# ESP32-S31 register map
Vendor: ESPRESSIF SYSTEMS (SHANGHAI) CO., LTD.; Series: ESP32 S-Series; File version: 1
CPU: RV32IMAFC r0p0, little endian, no MPU, FPU, 0 interrupt priority bits
Address unit: 32 bits
Registers are 32-bit, read-write, reset 0x0 unless marked. A register's access mark holds for its fields unless they carry their own. Offsets are from the block's base; [hi:lo] are bit positions.

## LP_PERICLKRST — LP_PERICLKRST Peripheral
Base 0x20710000
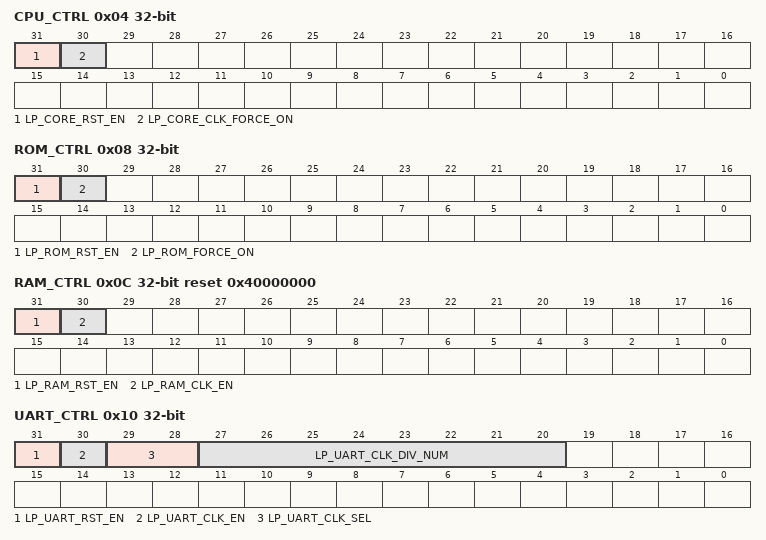
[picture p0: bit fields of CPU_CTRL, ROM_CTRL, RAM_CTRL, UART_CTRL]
0x04 CPU_CTRL access per field — need_des
  [31] LP_CORE_RST_EN wo — need_des
  [30] LP_CORE_CLK_FORCE_ON rw — need_des
0x08 ROM_CTRL — need_des
  [31] LP_ROM_RST_EN — need_des
  [30] LP_ROM_FORCE_ON — need_des
0x0C RAM_CTRL reset 0x40000000 — need_des
  [31] LP_RAM_RST_EN — need_des
  [30] LP_RAM_CLK_EN — need_des
0x10 UART_CTRL — need_des
  [31] LP_UART_RST_EN — need_des
  [30] LP_UART_CLK_EN — need_des
  [29:28] LP_UART_CLK_SEL — need_des
  [27:20] LP_UART_CLK_DIV_NUM — need_des
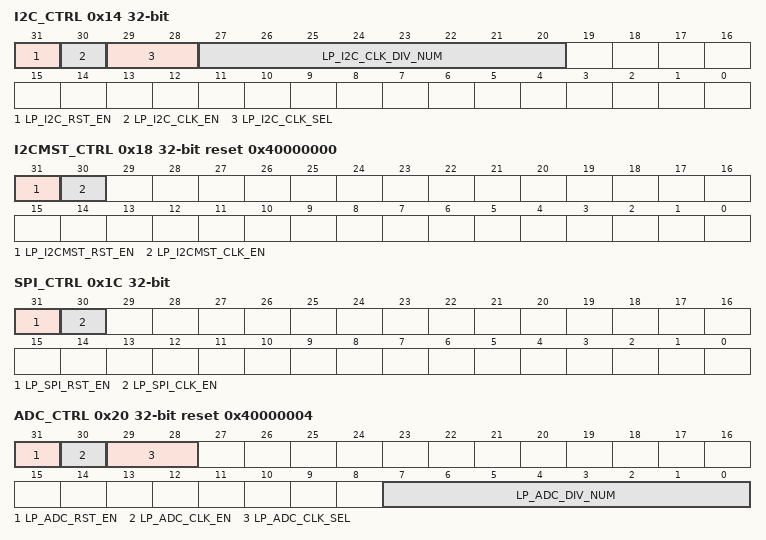
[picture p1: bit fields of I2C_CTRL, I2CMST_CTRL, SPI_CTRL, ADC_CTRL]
0x14 I2C_CTRL — need_des
  [31] LP_I2C_RST_EN — need_des
  [30] LP_I2C_CLK_EN — need_des
  [29:28] LP_I2C_CLK_SEL — need_des
  [27:20] LP_I2C_CLK_DIV_NUM — need_des
0x18 I2CMST_CTRL reset 0x40000000 — need_des
  [31] LP_I2CMST_RST_EN — need_des
  [30] LP_I2CMST_CLK_EN — need_des
0x1C SPI_CTRL — need_des
  [31] LP_SPI_RST_EN — need_des
  [30] LP_SPI_CLK_EN — need_des
0x20 ADC_CTRL reset 0x40000004 — need_des
  [31] LP_ADC_RST_EN — need_des
  [30] LP_ADC_CLK_EN — need_des
  [29:28] LP_ADC_CLK_SEL — need_des
  [7:0] LP_ADC_DIV_NUM — need_des
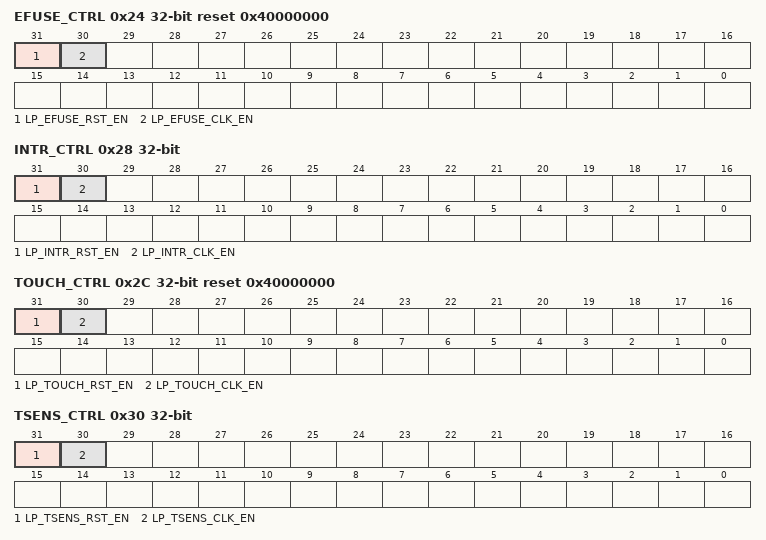
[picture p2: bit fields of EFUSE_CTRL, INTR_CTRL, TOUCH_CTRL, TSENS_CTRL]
0x24 EFUSE_CTRL reset 0x40000000 — need_des
  [31] LP_EFUSE_RST_EN — need_des
  [30] LP_EFUSE_CLK_EN — need_des
0x28 INTR_CTRL — need_des
  [31] LP_INTR_RST_EN — need_des
  [30] LP_INTR_CLK_EN — need_des
0x2C TOUCH_CTRL reset 0x40000000 — need_des
  [31] LP_TOUCH_RST_EN — need_des
  [30] LP_TOUCH_CLK_EN — need_des
0x30 TSENS_CTRL — need_des
  [31] LP_TSENS_RST_EN — need_des
  [30] LP_TSENS_CLK_EN — need_des
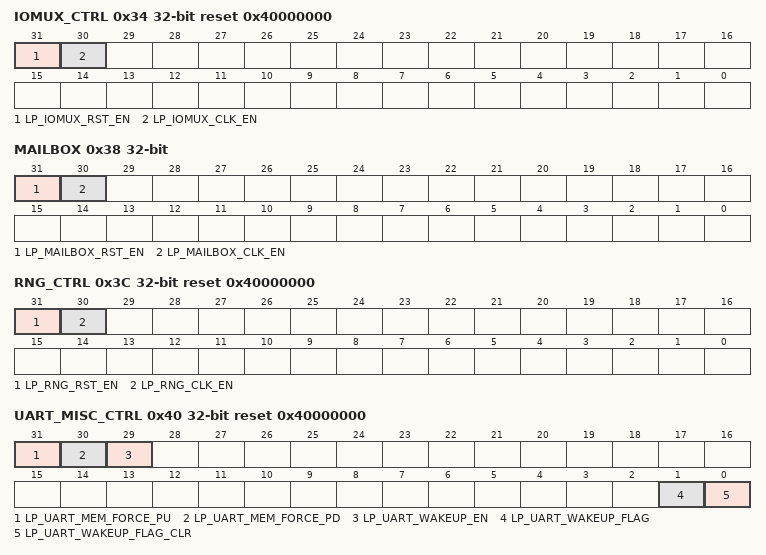
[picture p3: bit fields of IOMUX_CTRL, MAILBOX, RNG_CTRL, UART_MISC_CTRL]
0x34 IOMUX_CTRL reset 0x40000000 — need_des
  [31] LP_IOMUX_RST_EN — need_des
  [30] LP_IOMUX_CLK_EN — need_des
0x38 MAILBOX — need_des
  [31] LP_MAILBOX_RST_EN — need_des
  [30] LP_MAILBOX_CLK_EN — need_des
0x3C RNG_CTRL reset 0x40000000 — need_des
  [31] LP_RNG_RST_EN — need_des
  [30] LP_RNG_CLK_EN — need_des
0x40 UART_MISC_CTRL access per field reset 0x40000000 — need_des
  [31] LP_UART_MEM_FORCE_PU rw — need_des
  [30] LP_UART_MEM_FORCE_PD rw — need_des
  [29] LP_UART_WAKEUP_EN rw — need_des
  [1] LP_UART_WAKEUP_FLAG rw — need_des
  [0] LP_UART_WAKEUP_FLAG_CLR wo — need_des
0x44 CPU reset 0x80000000 — need_des
  [31] LPCORE_DBGM_UNAVAILABLE
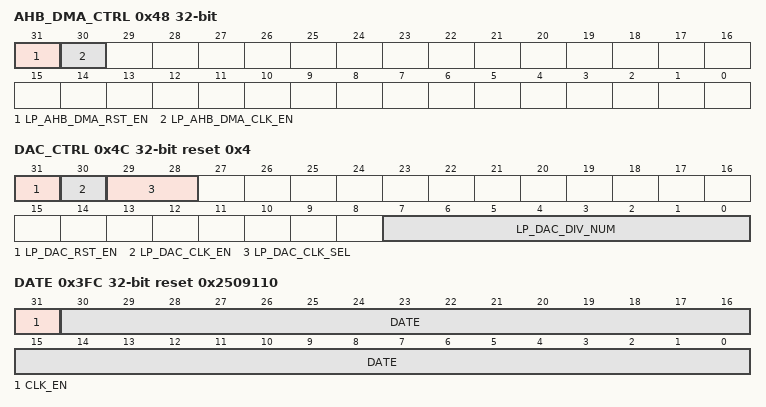
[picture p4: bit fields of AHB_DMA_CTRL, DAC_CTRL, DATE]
0x48 AHB_DMA_CTRL — need_des
  [31] LP_AHB_DMA_RST_EN — need_des
  [30] LP_AHB_DMA_CLK_EN — need_des
0x4C DAC_CTRL reset 0x4 — need_des
  [31] LP_DAC_RST_EN — need_des
  [30] LP_DAC_CLK_EN — need_des
  [29:28] LP_DAC_CLK_SEL — need_des
  [7:0] LP_DAC_DIV_NUM — need_des
0x50 DM_CTRL reset 0x80000000 — need_des
  [31] LP_DM_CLK_EN
0x3FC DATE reset 0x2509110 — need_des
  [31] CLK_EN — need_des
  [30:0] DATE — need_des

## LP_TEE — Low-power Trusted Execution Environment
Base 0x20706800
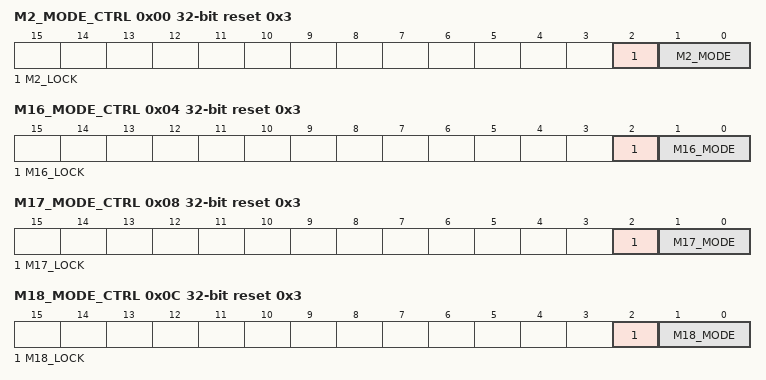
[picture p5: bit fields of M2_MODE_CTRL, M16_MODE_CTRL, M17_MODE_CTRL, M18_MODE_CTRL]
0x00 M2_MODE_CTRL reset 0x3 — TEE mode control register
  [2] M2_LOCK — Set 1 to lock m2 tee configuration
  [1:0] M2_MODE — Configures M0 security level mode.\\ 0: tee_mode \\ 1: ree_mode0 \\ 2: ree_mode1 \\ 3: ree_mode2 \\
0x04 M16_MODE_CTRL reset 0x3 — TEE mode control register
  [2] M16_LOCK — Set 1 to lock m16 tee configuration
  [1:0] M16_MODE — Configures M0 security level mode.\\ 0: tee_mode \\ 1: ree_mode0 \\ 2: ree_mode1 \\ 3: ree_mode2 \\
0x08 M17_MODE_CTRL reset 0x3 — TEE mode control register
  [2] M17_LOCK — Set 1 to lock m17 tee configuration
  [1:0] M17_MODE — Configures M0 security level mode.\\ 0: tee_mode \\ 1: ree_mode0 \\ 2: ree_mode1 \\ 3: ree_mode2 \\
0x0C M18_MODE_CTRL reset 0x3 — TEE mode control register
  [2] M18_LOCK — Set 1 to lock m18 tee configuration
  [1:0] M18_MODE — Configures M0 security level mode.\\ 0: tee_mode \\ 1: ree_mode0 \\ 2: ree_mode1 \\ 3: ree_mode2 \\
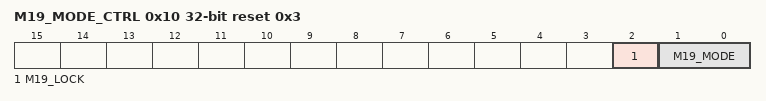
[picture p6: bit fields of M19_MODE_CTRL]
0x10 M19_MODE_CTRL reset 0x3 — TEE mode control register
  [2] M19_LOCK — Set 1 to lock m19 tee configuration
  [1:0] M19_MODE — Configures M0 security level mode.\\ 0: tee_mode \\ 1: ree_mode0 \\ 2: ree_mode1 \\ 3: ree_mode2 \\
0x14 FORCE_ACC_HP — Force access to hpmem configuration register
  [7:0] FORCE_ACC_HPMEM_EN — Configures whether to allow LP CPU to force access to HP_MEM regardless of permission management.\\ 0x5a: enable force access HP_MEM \\ other: disable force access HP_MEM \\
0x18 LP_GPIO_SECURITY — need des
  [7:0] LP_GPIO_LOCK — This field decides whether lp_gpio_config can be locked, or not. 0 (default): unlocked. 1: locked.
0x1C HP_GPIO_SECURITY_1 — need des
  [31:0] HP_GPIO_LOCK_P1 — This field decides whether hp_gpio_config of PIN0~31 can be locked, or not. 0 (default): unlocked. 1: locked.
0x20 HP_GPIO_SECURITY_2 — need des
  [30:0] HP_GPIO_LOCK_P2 — This field decides whether hp_gpio_config of PIN32~62 can be locked, or not. 0 (default): unlocked. 1: locked.
0x3F8 CLOCK_GATE reset 0x1 — Clock gating register
  [0] CLK_EN — Configures whether to keep the clock always on.\\ 0: enable automatic clock gating \\ 1: keep the clock always on \\
0x3FC DATE reset 0x2506240 — Version control register
  [27:0] DATE
